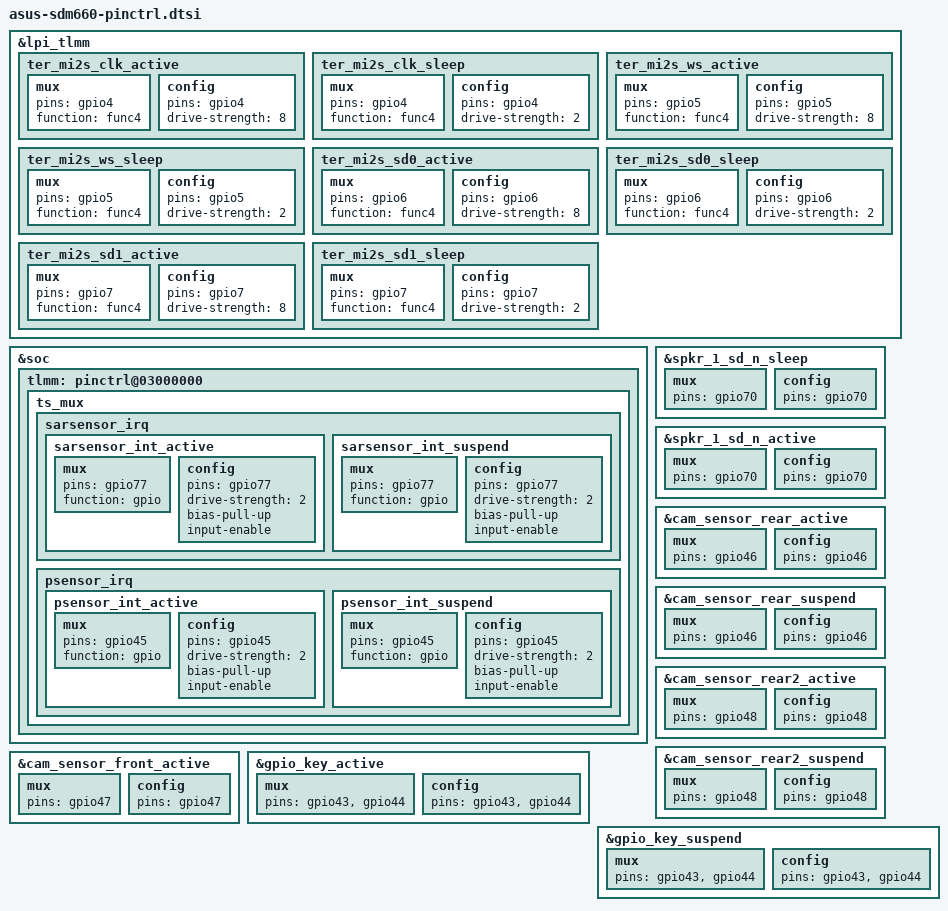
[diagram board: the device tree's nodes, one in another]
// SPDX-License-Identifier: GPL-2.0
// Copyright (C) 2021 Atom-X-Devs < https://www.github.com/Atom-X-Devs >
// Copyright (C) 2021 Atom-X-Devs < https://www.github.com/Atom-X-Devs >

// asus sdm660-lpi.dtsi specific diff
&lpi_tlmm {
	ter_mi2s_clk_active: ter_mi2s_clk_active {
		mux {
			pins = "gpio4";
			function = "func4";
		};

		config {
			pins = "gpio4";
			drive-strength = <8>;
		};
	};

	ter_mi2s_clk_sleep: ter_mi2s_clk_sleep {
		mux {
			pins = "gpio4";
			function = "func4";
		};

		config {
			pins = "gpio4";
			drive-strength = <2>;
		};
	};

	ter_mi2s_ws_active: ter_mi2s_ws_active {
		mux {
			pins = "gpio5";
			function = "func4";
		};

		config {
			pins = "gpio5";
			drive-strength = <8>;
		};
	};

	ter_mi2s_ws_sleep: ter_mi2s_ws_sleep {
		mux {
			pins = "gpio5";
			function = "func4";
		};

		config {
			pins = "gpio5";
			drive-strength = <2>;
		};
	};

	ter_mi2s_sd0_active: ter_mi2s_sd0_active {
		mux {
			pins = "gpio6";
			function = "func4";
		};

		config {
			pins = "gpio6";
			drive-strength = <8>;
		};
	};

	ter_mi2s_sd0_sleep: ter_mi2s_sd0_sleep {
		mux {
			pins = "gpio6";
			function = "func4";
		};

		config {
			pins = "gpio6";
			drive-strength = <2>;
		};
	};

	ter_mi2s_sd1_active: ter_mi2s_sd1_active {
		mux {
			pins = "gpio7";
			function = "func4";
		};

		config {
			pins = "gpio7";
			drive-strength = <8>;
		};
	};

	ter_mi2s_sd1_sleep: ter_mi2s_sd1_sleep {
		mux {
			pins = "gpio7";
			function = "func4";
		};

		config {
			pins = "gpio7";
			drive-strength = <2>;
		};
	};
};

// asus sdm660-lpi.dtsi specific diff
&soc {
	tlmm: pinctrl@03000000 {
		ts_mux {
			sarsensor_irq {
				sarsensor_int_active: sarsensor_int_active {
					mux {
						pins = "gpio77";
						function = "gpio";
					};

					config {
						pins = "gpio77";
						drive-strength = <2>;
						bias-pull-up;
						input-enable;
					};
				};

				sarsensor_int_suspend: sarsensor_int_suspend {
					mux {
						pins = "gpio77";
						function = "gpio";
					};

					config {
						pins = "gpio77";
						drive-strength = <2>;
						bias-pull-up;
						input-enable;
					};
				};
			};

			psensor_irq {
				psensor_int_active: psensor_int_active {
					mux {
						pins = "gpio45";
						function = "gpio";
					};

					config {
						pins = "gpio45";
						drive-strength = <2>;
						bias-pull-up;
						input-enable;
					};
				};

				psensor_int_suspend: psensor_int_suspend {
					mux {
						pins = "gpio45";
						function = "gpio";
					};

					config {
						pins = "gpio45";
						drive-strength = <2>;
						bias-pull-up;
						input-enable;
					};
				};
			};
		};
	};
};

&spkr_1_sd_n_sleep {
	mux {
		pins = "gpio70";
	};

	config {
		pins = "gpio70";
	};
};

&spkr_1_sd_n_active {
	mux {
		pins = "gpio70";
	};

	config {
		pins = "gpio70";
	};
};

&cam_sensor_rear_active {
	mux {
		pins = "gpio46";
	};

	config {
		pins = "gpio46";
	};
};

&cam_sensor_rear_suspend {
	mux {
		pins = "gpio46";
	};

	config {
		pins = "gpio46";
	};
};

&cam_sensor_rear2_active {
	/* RESET */
	mux {
		pins = "gpio48";
	};

	config {
		pins = "gpio48";
	};
};

&cam_sensor_rear2_suspend {
	/* RESET */
	mux {
		pins = "gpio48";
	};

	config {
		pins = "gpio48";
	};
};

&cam_sensor_front_active {
	mux {
		pins = "gpio47";
	};

	config {
		pins = "gpio47";
	};
};

&gpio_key_active {
	mux {
		pins = "gpio43", "gpio44";
	};

	config {
		pins = "gpio43", "gpio44";
	};
};

&gpio_key_suspend {
	mux {
		pins = "gpio43", "gpio44";
	};

	config {
		pins = "gpio43", "gpio44";
	};
};
